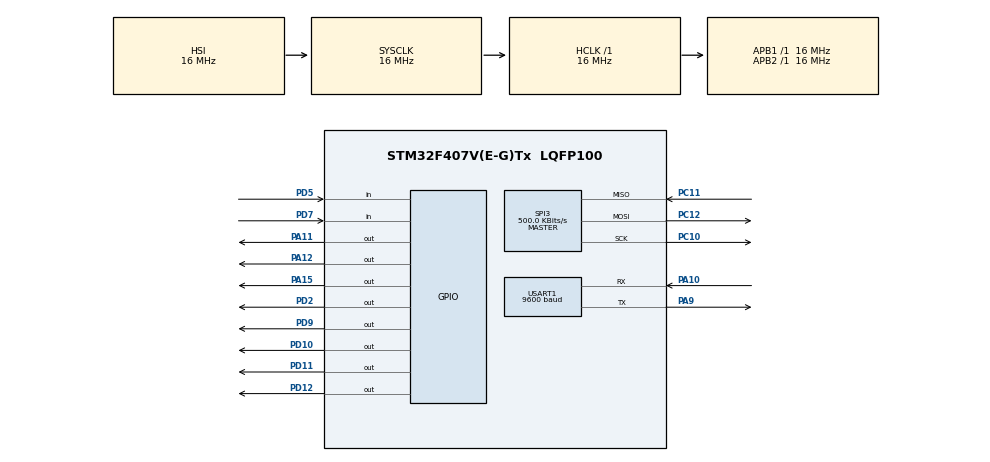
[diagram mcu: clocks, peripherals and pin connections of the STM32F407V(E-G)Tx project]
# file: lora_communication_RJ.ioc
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Mcu.Family=STM32F4
Mcu.Name=STM32F407V(E-G)Tx
Mcu.Package=LQFP100
NVIC.PriorityGroup=NVIC_PRIORITYGROUP_4
PA10.Mode=Asynchronous
PA10.Signal=USART1_RX
PA11.PinState=GPIO_PIN_SET
PA11.Signal=GPIO_Output
PA12.Signal=GPIO_Output
PA15.GPIO_PuPd=GPIO_NOPULL
PA15.PinState=GPIO_PIN_SET
PA15.Signal=GPIO_Output
PA9.Mode=Asynchronous
PA9.Signal=USART1_TX
PC10.Mode=Full_Duplex_Master
PC10.Signal=SPI3_SCK
PC11.Mode=Full_Duplex_Master
PC11.Signal=SPI3_MISO
PC12.Mode=Full_Duplex_Master
PC12.Signal=SPI3_MOSI
PD10.Signal=GPIO_Output
PD11.Signal=GPIO_Output
PD12.Signal=GPIO_Output
PD2.PinState=GPIO_PIN_SET
PD2.Signal=GPIO_Output
PD5.Signal=GPIO_Input
PD7.Signal=GPIO_Input
PD9.Signal=GPIO_Output
ProjectManager.HeapSize=0x200
ProjectManager.StackSize=0x400
ProjectManager.TargetToolchain=STM32CubeIDE
RCC.48MHZClocksFreq_Value=48000000
RCC.AHBFreq_Value=16000000
RCC.APB1Freq_Value=16000000
RCC.APB1TimFreq_Value=16000000
RCC.APB2Freq_Value=16000000
RCC.APB2TimFreq_Value=16000000
RCC.CortexFreq_Value=16000000
RCC.HCLKFreq_Value=16000000
RCC.HSE_VALUE=25000000
RCC.HSI_VALUE=16000000
RCC.LSE_VALUE=32768
RCC.SYSCLKFreq_VALUE=16000000
RCC.VCOOutputFreq_Value=192000000
SPI3.BaudRatePrescaler=SPI_BAUDRATEPRESCALER_32
SPI3.CalculateBaudRate=500.0 KBits/s
SPI3.Direction=SPI_DIRECTION_2LINES
SPI3.Mode=SPI_MODE_MASTER
SPI3.VirtualType=VM_MASTER
USART1.BaudRate=9600
USART1.VirtualMode=VM_ASYNC
board=custom

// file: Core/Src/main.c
/* USER CODE BEGIN Header */
/**
  ******************************************************************************
  * @file           : main.c
  * @brief          : Main program body
  ******************************************************************************
  * @attention
  *
  * Copyright (c) 2026 STMicroelectronics.
  * All rights reserved.
  *
  * This software is licensed under terms that can be found in the LICENSE file
  * in the root directory of this software component.
  * If no LICENSE file comes with this software, it is provided AS-IS.
  *
  ******************************************************************************
  */
/* USER CODE END Header */
#include "main.h"

/* USER CODE BEGIN Includes */
#include "slave_side.h"
#include "Motor.h"
#include "sa818s.h"

/* USER CODE END Includes */

SPI_HandleTypeDef hspi3;

UART_HandleTypeDef huart1;

void SystemClock_Config(void);
static void MX_GPIO_Init(void);
static void MX_SPI3_Init(void);
static void MX_USART1_UART_Init(void);

int main(void)
{

  /* MCU Configuration--------------------------------------------------------*/

  /* Reset of all peripherals, Initializes the Flash interface and the Systick. */
  HAL_Init();

  /* Configure the system clock */
  SystemClock_Config();

  /* Initialize all configured peripherals */
  MX_GPIO_Init();
  MX_SPI3_Init();
  MX_USART1_UART_Init();
  /* USER CODE BEGIN 2 */
  Slave_App_Init();

  if(SA818_Init() != HAL_OK)
  {
      while(1); // error
  }

  SA818_SetHighPower();
  /* USER CODE END 2 */

  /* Infinite loop */
  /* USER CODE BEGIN WHILE */
  while (1)
  {
	  LORA_RX_Poll();
	  Motor_Task();
	 // Slave_App_Loop();

    /* USER CODE END WHILE */

  }
}

void SystemClock_Config(void)
{
  RCC_OscInitTypeDef RCC_OscInitStruct = {0};
  RCC_ClkInitTypeDef RCC_ClkInitStruct = {0};

  /** Configure the main internal regulator output voltage
  */
  __HAL_RCC_PWR_CLK_ENABLE();
  __HAL_PWR_VOLTAGESCALING_CONFIG(PWR_REGULATOR_VOLTAGE_SCALE1);

  /** Initializes the RCC Oscillators according to the specified parameters
  * in the RCC_OscInitTypeDef structure.
  */
  RCC_OscInitStruct.OscillatorType = RCC_OSCILLATORTYPE_HSI;
  RCC_OscInitStruct.HSIState = RCC_HSI_ON;
  RCC_OscInitStruct.HSICalibrationValue = RCC_HSICALIBRATION_DEFAULT;
  RCC_OscInitStruct.PLL.PLLState = RCC_PLL_NONE;
  if (HAL_RCC_OscConfig(&RCC_OscInitStruct) != HAL_OK)
  {
    Error_Handler();
  }

  /** Initializes the CPU, AHB and APB buses clocks
  */
  RCC_ClkInitStruct.ClockType = RCC_CLOCKTYPE_HCLK|RCC_CLOCKTYPE_SYSCLK
                              |RCC_CLOCKTYPE_PCLK1|RCC_CLOCKTYPE_PCLK2;
  RCC_ClkInitStruct.SYSCLKSource = RCC_SYSCLKSOURCE_HSI;
  RCC_ClkInitStruct.AHBCLKDivider = RCC_SYSCLK_DIV1;
  RCC_ClkInitStruct.APB1CLKDivider = RCC_HCLK_DIV1;
  RCC_ClkInitStruct.APB2CLKDivider = RCC_HCLK_DIV1;

  if (HAL_RCC_ClockConfig(&RCC_ClkInitStruct, FLASH_LATENCY_0) != HAL_OK)
  {
    Error_Handler();
  }
}

static void MX_SPI3_Init(void)
{

  /* SPI3 parameter configuration*/
  hspi3.Instance = SPI3;
  hspi3.Init.Mode = SPI_MODE_MASTER;
  hspi3.Init.Direction = SPI_DIRECTION_2LINES;
  hspi3.Init.DataSize = SPI_DATASIZE_8BIT;
  hspi3.Init.CLKPolarity = SPI_POLARITY_LOW;
  hspi3.Init.CLKPhase = SPI_PHASE_1EDGE;
  hspi3.Init.NSS = SPI_NSS_SOFT;
  hspi3.Init.BaudRatePrescaler = SPI_BAUDRATEPRESCALER_32;
  hspi3.Init.FirstBit = SPI_FIRSTBIT_MSB;
  hspi3.Init.TIMode = SPI_TIMODE_DISABLE;
  hspi3.Init.CRCCalculation = SPI_CRCCALCULATION_DISABLE;
  hspi3.Init.CRCPolynomial = 10;
  if (HAL_SPI_Init(&hspi3) != HAL_OK)
  {
    Error_Handler();
  }

}

static void MX_USART1_UART_Init(void)
{

  huart1.Instance = USART1;
  huart1.Init.BaudRate = 9600;
  huart1.Init.WordLength = UART_WORDLENGTH_8B;
  huart1.Init.StopBits = UART_STOPBITS_1;
  huart1.Init.Parity = UART_PARITY_NONE;
  huart1.Init.Mode = UART_MODE_TX_RX;
  huart1.Init.HwFlowCtl = UART_HWCONTROL_NONE;
  huart1.Init.OverSampling = UART_OVERSAMPLING_16;
  if (HAL_UART_Init(&huart1) != HAL_OK)
  {
    Error_Handler();
  }

}

static void MX_GPIO_Init(void)
{
  GPIO_InitTypeDef GPIO_InitStruct = {0};

  /* GPIO Ports Clock Enable */
  __HAL_RCC_GPIOD_CLK_ENABLE();
  __HAL_RCC_GPIOA_CLK_ENABLE();
  __HAL_RCC_GPIOC_CLK_ENABLE();

  /*Configure GPIO pin Output Level */
  HAL_GPIO_WritePin(GPIOD, GPIO_PIN_9|GPIO_PIN_10|GPIO_PIN_11|GPIO_PIN_12, GPIO_PIN_RESET);

  /*Configure GPIO pin Output Level */
  HAL_GPIO_WritePin(GPIOA, GPIO_PIN_11|GPIO_PIN_15, GPIO_PIN_SET);

  /*Configure GPIO pin Output Level */
  HAL_GPIO_WritePin(GPIOA, GPIO_PIN_12, GPIO_PIN_RESET);

  /*Configure GPIO pin Output Level */
  HAL_GPIO_WritePin(GPIOD, GPIO_PIN_2, GPIO_PIN_SET);

  /*Configure GPIO pins : PD9 PD10 PD11 PD12
                           PD2 */
  GPIO_InitStruct.Pin = GPIO_PIN_9|GPIO_PIN_10|GPIO_PIN_11|GPIO_PIN_12
                          |GPIO_PIN_2;
  GPIO_InitStruct.Mode = GPIO_MODE_OUTPUT_PP;
  GPIO_InitStruct.Pull = GPIO_NOPULL;
  GPIO_InitStruct.Speed = GPIO_SPEED_FREQ_LOW;
  HAL_GPIO_Init(GPIOD, &GPIO_InitStruct);

  /*Configure GPIO pins : PA11 PA12 PA15 */
  GPIO_InitStruct.Pin = GPIO_PIN_11|GPIO_PIN_12|GPIO_PIN_15;
  GPIO_InitStruct.Mode = GPIO_MODE_OUTPUT_PP;
  GPIO_InitStruct.Pull = GPIO_NOPULL;
  GPIO_InitStruct.Speed = GPIO_SPEED_FREQ_LOW;
  HAL_GPIO_Init(GPIOA, &GPIO_InitStruct);

  /*Configure GPIO pins : PD5 PD7 */
  GPIO_InitStruct.Pin = GPIO_PIN_5|GPIO_PIN_7;
  GPIO_InitStruct.Mode = GPIO_MODE_INPUT;
  GPIO_InitStruct.Pull = GPIO_NOPULL;
  HAL_GPIO_Init(GPIOD, &GPIO_InitStruct);

}

void Error_Handler(void)
{
  __disable_irq();
  while (1)
  {
  }
}
